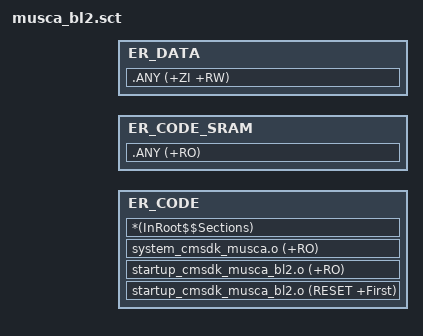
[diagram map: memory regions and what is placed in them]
#! armclang --target=arm-arm-none-eabi -march=armv8-m.main -E -xc

/*
 * Copyright (c) 2018 Arm Limited. All rights reserved.
 *
 * Licensed under the Apache License, Version 2.0 (the "License");
 * you may not use this file except in compliance with the License.
 * You may obtain a copy of the License at
 *
 *     http://www.apache.org/licenses/LICENSE-2.0
 *
 * Unless required by applicable law or agreed to in writing, software
 * distributed under the License is distributed on an "AS IS" BASIS,
 * WITHOUT WARRANTIES OR CONDITIONS OF ANY KIND, either express or implied.
 * See the License for the specific language governing permissions and
 * limitations under the License.
 */

#include "region_defs.h"

LR_CODE BL2_CODE_START {
    ER_CODE BL2_CODE_START {
        startup_cmsdk_musca_bl2.o (RESET +First)
        startup_cmsdk_musca_bl2.o (+RO)
        system_cmsdk_musca.o (+RO)             ; SystemInit
        *(InRoot$$Sections)                    ; ARM library sections
    }

    ER_CODE_SRAM BL2_CODE_SRAM_BASE {
        .ANY (+RO) ; app code that gets copied from Flash to SRAM
    }

    ER_DATA BL2_DATA_START BL2_DATA_SIZE {
        .ANY (+ZI +RW)
    }
}
